AUTOSAR XML (schema 00048)
package /ComponentTypes
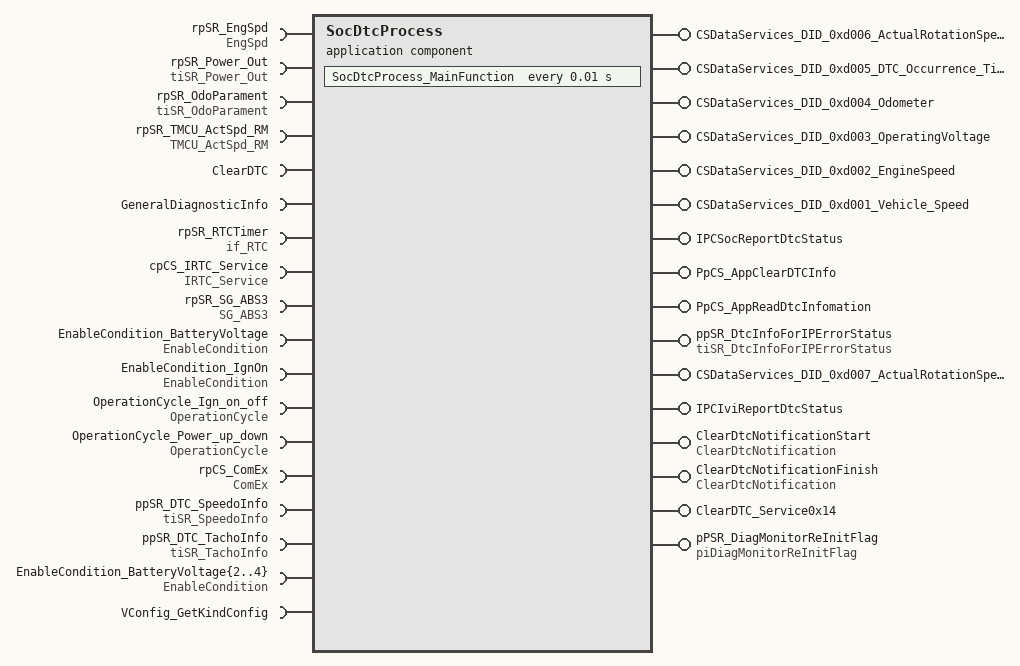
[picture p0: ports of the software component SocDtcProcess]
  application sw component type SocDtcProcess
    7 x provide port:
      CSDataServices_DID_0xd006_ActualRotationSpeed: server-com-spec{operation=ReadData, queue-length=1}, provided-interface=CSDataServices_DID_0xd006_ActualRotationSpeed
      CSDataServices_DID_0xd005_DTC_Occurrence_Timer: server-com-spec{operation=ReadData, queue-length=1}, provided-interface=CSDataServices_DID_0xd005_DTC_Occurrence_Timer
      CSDataServices_DID_0xd004_Odometer: server-com-spec{operation=ReadData, queue-length=1}, provided-interface=CSDataServices_DID_0xd004_Odometer
      CSDataServices_DID_0xd003_OperatingVoltage: server-com-spec{operation=ReadData, queue-length=1}, provided-interface=CSDataServices_DID_0xd003_OperatingVoltage
      CSDataServices_DID_0xd002_EngineSpeed: server-com-spec{operation=ReadData, queue-length=1}, provided-interface=CSDataServices_DID_0xd002_EngineSpeed
      CSDataServices_DID_0xd001_Vehicle_Speed: server-com-spec{operation=ReadData, queue-length=1}, provided-interface=CSDataServices_DID_0xd001_Vehicle_Speed
      IPCSocReportDtcStatus: server-com-spec{operation=IpcSocReportDtcStatus, queue-length=1}, provided-interface=IPCSocReportDtcStatus
    6 x require port:
      rpSR_EngSpd: nonqueued-receiver-com-spec{data-element=EngSpd, alive-timeout=100, filter=data-filter-type=ALWAYS, handle-never-received=true, init-value=0}, required-interface=EngSpd
      rpSR_Power_Out: nonqueued-receiver-com-spec{data-element=SystemStateOut, alive-timeout=100, filter=data-filter-type=ALWAYS, init-value=constant-reference=PowerOutInit}, required-interface=tiSR_Power_Out
      rpSR_OdoParament: nonqueued-receiver-com-spec{data-element=Element, alive-timeout=100, filter=data-filter-type=ALWAYS, handle-never-received=true, init-value=constant-reference=SocRpOdoDataInit}, required-interface=tiSR_OdoParament
      rpSR_TMCU_ActSpd_RM: nonqueued-receiver-com-spec{data-element=TMCU_ActSpd_RM, alive-timeout=100, filter=data-filter-type=ALWAYS, handle-never-received=true, init-value=0}, required-interface=TMCU_ActSpd_RM
      ClearDTC: required-com-specs=[SelectDTC, ClearDTC], required-interface=ClearDTC
      GeneralDiagnosticInfo: required-interface=GeneralDiagnosticInfo
        required-com-specs:
          GetMonitorStatus
          GetDebouncingOfEvent
          GetEventEnableCondition
          GetEventExtendedDataRecordEx
          GetEventFreezeFrameDataEx
          GetFaultDetectionCounter
          GetDTCOfEvent
          GetEventTested
          GetEventFailed
          GetEventStatus
          GetEventUdsStatus
    provide port PpCS_AppClearDTCInfo: server-com-spec{operation=AppClearDTCInfo, queue-length=1}, provided-interface=PpCS_AppClearDTCInfo
    provide port PpCS_AppReadDtcInfomation: server-com-spec{operation=AppReadDtcInformation, queue-length=1}, provided-interface=PpCS_AppReadDtcInfomation
    require port rpSR_RTCTimer: required-interface=if_RTC
      required-com-specs:
        data-element=SleepDateTime, filter=data-filter-type=ALWAYS, init-value=0
        data-element=UtcTime, filter=data-filter-type=ALWAYS
    require port cpCS_IRTC_Service: required-com-specs=[UTC2PerpetualCalendar, GetUTCTimeInMillis], required-interface=IRTC_Service
    provide port ppSR_DtcInfoForIPErrorStatus: nonqueued-sender-com-spec{data-element=Element, init-value=0}, provided-interface=tiSR_DtcInfoForIPErrorStatus
    5 x require port:
      rpSR_SG_ABS3: nonqueued-receiver-com-spec{data-element=SG_ABS3, alive-timeout=0.2, enable-update=true, handle-never-received=true, init-value=fields=[ABSActv_0x265:0, ABSFailSts_0x265:1, CheckSum_ABS3_0x265:0, dummy_ABS3_0:0, dummy_ABS3_1:0, dummy_ABS3_2:0, dummy_ABS3_3:0, EBDActv_0x265:0, EBDFailSts_0x265:0, RollingCounter_ABS3_0x265:0, VehOdoInfo_0x265:0, VehOdoInfoSts_0x265:1, VehSpd_0x265:0, VehSpdVld_0x265:0]}, required-interface=SG_ABS3
      EnableCondition_BatteryVoltage: client-com-spec=SetEnableCondition, required-interface=EnableCondition
      EnableCondition_IgnOn: client-com-spec=SetEnableCondition, required-interface=EnableCondition
      OperationCycle_Ign_on_off: required-com-specs=[SetOperationCycleState, GetOperationCycleState], required-interface=OperationCycle
      OperationCycle_Power_up_down: required-com-specs=[SetOperationCycleState, GetOperationCycleState], required-interface=OperationCycle
    6 x provide port:
      CSDataServices_DID_0xd007_ActualRotationSpeed02: server-com-spec{operation=ReadData, queue-length=1}, provided-interface=CSDataServices_DID_0xd007_ActualRotationSpeed02
      IPCIviReportDtcStatus: server-com-spec{operation=IpcIviReportDtcSts, queue-length=1}, provided-interface=IPCIviReportDtcStatus
      ClearDtcNotificationStart: server-com-spec{operation=ClearDtcNotification, queue-length=1}, provided-interface=ClearDtcNotification
      ClearDtcNotificationFinish: server-com-spec{operation=ClearDtcNotification, queue-length=1}, provided-interface=ClearDtcNotification
      ClearDTC_Service0x14: nonqueued-sender-com-spec{data-element=StatusFlag, init-value=0}, provided-interface=ClearDTC_Service0x14
      pPSR_DiagMonitorReInitFlag: nonqueued-sender-com-spec{data-element=ChangeCounter, init-value=0}, provided-interface=piDiagMonitorReInitFlag
    7 x require port:
      rpCS_ComEx: required-com-specs=[SendSignal, ReceiveSignal, GetRxE2EStatus], required-interface=ComEx
      ppSR_DTC_SpeedoInfo: nonqueued-receiver-com-spec{data-element=Element, filter=data-filter-type=ALWAYS, init-value=fields=[OverSpdWrnFlg:0, VehRunSts:0, IndicateSpeed:0, RealSpeed:0, IndicateSpeedMile:0, RealSpeedMile:0, RealSpeedBak:0, Msg_missingSts:0, VehSpdVld:0]}, required-interface=tiSR_SpeedoInfo
      ppSR_DTC_TachoInfo: nonqueued-receiver-com-spec{data-element=Element, filter=data-filter-type=ALWAYS, init-value=fields=[EngRunSts:0, EngSpd:0, TimeOutFlag:0, EngSpdBak:0, Msg_missingSts:0]}, required-interface=tiSR_TachoInfo
      EnableCondition_BatteryVoltage{2..4}: client-com-spec=SetEnableCondition, required-interface=EnableCondition
      VConfig_GetKindConfig: client-com-spec=Operation_VConfig_GetKindConfig, required-interface=VConfig_GetKindConfig
    behavior SocDtcProcess_InternalBehavior
      exclusive area SocDtcPorcessExclusiveArea
      init event SocDtcProcess_InitEvent: start-on-event=SocDtcProcess_Init
      timing event TMT_SocDtcProcess_MainFunction: start-on-event=SocDtcProcess_MainFunction, period=0.01
      13 x operation invoked event:
        OIT_CSDataServices_DID_0xd006_ActualRotationSpeed_ReadData_CSDataServices_DID_0xd006_ActualRotationSpeed_ReadData: start-on-event=CSDataServices_DID_0xd006_ActualRotationSpeed_ReadData, operation=CSDataServices_DID_0xd006_ActualRotationSpeed.ReadData
        OIT_CSDataServices_DID_0xd001_Vehicle_Speed_ReadData_CSDataServices_DID_0xd001_Vehicle_Speed_ReadData: start-on-event=CSDataServices_DID_0xd001_Vehicle_Speed_ReadData, operation=CSDataServices_DID_0xd001_Vehicle_Speed.ReadData
        OIT_CSDataServices_DID_0xd004_Odometer_ReadData_CSDataServices_DID_0xd004_Odometer_ReadData: start-on-event=CSDataServices_DID_0xd004_Odometer_ReadData, operation=CSDataServices_DID_0xd004_Odometer.ReadData
        OIT_CSDataServices_DID_0xd005_DTC_Occurrence_Timer_ReadData_CSDataServices_DID_0xd005_DTC_Occurrence_Timer_ReadData: start-on-event=CSDataServices_DID_0xd005_DTC_Occurrence_Timer_ReadData, operation=CSDataServices_DID_0xd005_DTC_Occurrence_Timer.ReadData
        OIT_CSDataServices_DID_0xd003_OperatingVoltage_ReadData_CSDataServices_DID_0xd003_OperatingVoltage_ReadData: start-on-event=CSDataServices_DID_0xd003_OperatingVoltage_ReadData, operation=CSDataServices_DID_0xd003_OperatingVoltage.ReadData
        OIT_CSDataServices_DID_0xd002_EngineSpeed_ReadData_CSDataServices_DID_0xd002_EngineSpeed_ReadData: start-on-event=CSDataServices_DID_0xd002_EngineSpeed_ReadData, operation=CSDataServices_DID_0xd002_EngineSpeed.ReadData
        OIT_IPCSocReportDtcStatus_IpcSocReportDtcStatus_IPCSocReportDtcStatus_IpcSocReportDtcStatus: start-on-event=IPCSocReportDtcStatus_IpcSocReportDtcStatus, operation=IPCSocReportDtcStatus.IpcSocReportDtcStatus
        OIT_PpCS_AppClearDTCInfo_AppClearDTCInfo_PpCS_AppClearDTCInfo_AppClearDTCInfo: start-on-event=PpCS_AppClearDTCInfo_AppClearDTCInfo, operation=PpCS_AppClearDTCInfo.AppClearDTCInfo
        OIT_PpCS_AppReadDtcInfomation_AppReadDtcInformation_PpCS_AppReadDtcInfomation_AppReadDtcInformation: start-on-event=PpCS_AppReadDtcInfomation_AppReadDtcInformation, operation=PpCS_AppReadDtcInfomation.AppReadDtcInformation
        OIT_CSDataServices_DID_0xd007_ActualRotationSpeed02_ReadData_CSDataServices_DID_0xd007_ActualRotationSpeed02_ReadData: start-on-event=CSDataServices_DID_0xd007_ActualRotationSpeed02_ReadData, operation=CSDataServices_DID_0xd007_ActualRotationSpeed02.ReadData
        OIT_IPCIviReportDtcStatus_IpcIviReportDtcSts_IPCIviReportDtcStatus_IpcIviReportDtcSts: start-on-event=IPCIviReportDtcStatus_IpcIviReportDtcSts, operation=IPCIviReportDtcStatus.IpcIviReportDtcSts
        OIT_ClearDtcNotificationStart_ClearDtcNotification_ClearDtcNotificationStart_ClearDtcNotification: start-on-event=ClearDtcNotificationStart_ClearDtcNotification, operation=ClearDtcNotificationStart.ClearDtcNotification
        OIT_ClearDtcNotificationFinish_ClearDtcNotification_ClearDtcNotificationFinish_ClearDtcNotification: start-on-event=ClearDtcNotificationFinish_ClearDtcNotification, operation=ClearDtcNotificationFinish.ClearDtcNotification
      port-api-options:
        enable-take-address=true, error-handling=NO-TRANSFORMER-ERROR-HANDLING, indirect-api=false, port=CSDataServices_DID_0xd001_Vehicle_Speed
        enable-take-address=true, error-handling=NO-TRANSFORMER-ERROR-HANDLING, indirect-api=false, port=CSDataServices_DID_0xd002_EngineSpeed
        enable-take-address=true, error-handling=NO-TRANSFORMER-ERROR-HANDLING, indirect-api=false, port=CSDataServices_DID_0xd003_OperatingVoltage
        enable-take-address=true, error-handling=NO-TRANSFORMER-ERROR-HANDLING, indirect-api=false, port=CSDataServices_DID_0xd004_Odometer
        enable-take-address=true, error-handling=NO-TRANSFORMER-ERROR-HANDLING, indirect-api=false, port=CSDataServices_DID_0xd005_DTC_Occurrence_Timer
        enable-take-address=true, error-handling=NO-TRANSFORMER-ERROR-HANDLING, indirect-api=false, port=CSDataServices_DID_0xd006_ActualRotationSpeed
        enable-take-address=true, error-handling=NO-TRANSFORMER-ERROR-HANDLING, indirect-api=false, port=PpCS_AppClearDTCInfo
        enable-take-address=true, error-handling=NO-TRANSFORMER-ERROR-HANDLING, indirect-api=false, port=PpCS_AppReadDtcInfomation
        enable-take-address=true, error-handling=NO-TRANSFORMER-ERROR-HANDLING, indirect-api=false, port=IPCIviReportDtcStatus
        enable-take-address=true, error-handling=NO-TRANSFORMER-ERROR-HANDLING, indirect-api=false, port=pPSR_DiagMonitorReInitFlag
      15 x runnable:
        SocDtcProcess_Init
        SocDtcProcess_MainFunction
          data-receive-point-by-arguments:
            9 x access:
              REC_rpSR_EngSpd_EngSpd: accessed-variable=rpSR_EngSpd.EngSpd
              REC_rpSR_Power_Out_SystemStateOut: accessed-variable=rpSR_Power_Out.SystemStateOut
              REC_rpSR_OdoParament_Element: accessed-variable=rpSR_OdoParament.Element
              REC_rpSR_TMCU_ActSpd_RM_TMCU_ActSpd_RM: accessed-variable=rpSR_TMCU_ActSpd_RM.TMCU_ActSpd_RM
              REC_rpSR_SG_ABS3_SG_ABS3: accessed-variable=rpSR_SG_ABS3.SG_ABS3
              REC_rpSR_RTCTimer_SleepDateTime: accessed-variable=rpSR_RTCTimer.SleepDateTime
              REC_rpSR_RTCTimer_UtcTime: accessed-variable=rpSR_RTCTimer.UtcTime
              REC_ppSR_DTC_SpeedoInfo_Element: accessed-variable=ppSR_DTC_SpeedoInfo.Element
              REC_ppSR_DTC_TachoInfo_Element: accessed-variable=ppSR_DTC_TachoInfo.Element
          data-send-points:
            access SEND_ppSR_DtcInfoForIPErrorStatus_Element: accessed-variable=ppSR_DtcInfoForIPErrorStatus.Element
            access SEND_pPSR_kl15OperationCycleChangeFlag_Element: accessed-variable=pPSR_DiagMonitorReInitFlag.ChangeCounter
          14 x sync call:
            SC_EnableCondition_SetEnableCondition: operation=EnableCondition_BatteryVoltage.SetEnableCondition
            SC_EnableCondition_IgnOn_SetEnableCondition: operation=EnableCondition_IgnOn.SetEnableCondition
            SC_OperationCycle_Ign_on_off_GetOperationCycleState: operation=OperationCycle_Ign_on_off.GetOperationCycleState
            SC_OperationCycle_Ign_on_off_SetOperationCycleState: operation=OperationCycle_Ign_on_off.SetOperationCycleState
            SC_OperationCycle_Power_up_down_GetOperationCycleState: operation=OperationCycle_Power_up_down.GetOperationCycleState
            SC_OperationCycle_Power_up_down_SetOperationCycleState: operation=OperationCycle_Power_up_down.SetOperationCycleState
            SC_rpCS_ComEx_GetRxE2EStatus: operation=rpCS_ComEx.GetRxE2EStatus
            SC_rpCS_ComEx_ReceiveSignal: operation=rpCS_ComEx.ReceiveSignal
            SC_rpCS_ComEx_SendSignal: operation=rpCS_ComEx.SendSignal
            SC_cpCS_IRTC_Service_UTC2PerpetualCalendar: operation=cpCS_IRTC_Service.UTC2PerpetualCalendar
            SC_EnableCondition_BatteryVoltage{2..4}_SetEnableCondition: operation=EnableCondition_BatteryVoltage{2..4}.SetEnableCondition
            SC_VConfig_GetKindConfig_Operation_VConfig_GetKindConfig: operation=VConfig_GetKindConfig.Operation_VConfig_GetKindConfig
        CSDataServices_DID_0xd006_ActualRotationSpeed_ReadData: can-be-invoked-concurrently=true
        CSDataServices_DID_0xd001_Vehicle_Speed_ReadData: can-be-invoked-concurrently=true
        CSDataServices_DID_0xd004_Odometer_ReadData: can-be-invoked-concurrently=true
        CSDataServices_DID_0xd005_DTC_Occurrence_Timer_ReadData: can-be-invoked-concurrently=true
          data-receive-point-by-arguments:
            access REC_rpSR_RTCTimer_UtcTime: accessed-variable=rpSR_RTCTimer.UtcTime
          sync call SC_cpCS_IRTC_Service_UTC2PerpetualCalendar: operation=cpCS_IRTC_Service.UTC2PerpetualCalendar
        CSDataServices_DID_0xd003_OperatingVoltage_ReadData: can-be-invoked-concurrently=true
        CSDataServices_DID_0xd002_EngineSpeed_ReadData: can-be-invoked-concurrently=true
        IPCSocReportDtcStatus_IpcSocReportDtcStatus
        PpCS_AppClearDTCInfo_AppClearDTCInfo
          sync call SC_ClearDTC_ClearDTC: operation=ClearDTC.ClearDTC
          sync call SC_ClearDTC_SelectDTC: operation=ClearDTC.SelectDTC
        PpCS_AppReadDtcInfomation_AppReadDtcInformation: can-enter-exclusive-area=SocDtcPorcessExclusiveArea
          11 x sync call:
            SC_GeneralDiagnosticInfo_GetDTCOfEvent: operation=GeneralDiagnosticInfo.GetDTCOfEvent
            SC_GeneralDiagnosticInfo_GetDebouncingOfEvent: operation=GeneralDiagnosticInfo.GetDebouncingOfEvent
            SC_GeneralDiagnosticInfo_GetEventEnableCondition: operation=GeneralDiagnosticInfo.GetEventEnableCondition
            SC_GeneralDiagnosticInfo_GetEventExtendedDataRecordEx: operation=GeneralDiagnosticInfo.GetEventExtendedDataRecordEx
            SC_GeneralDiagnosticInfo_GetEventFailed: operation=GeneralDiagnosticInfo.GetEventFailed
            SC_GeneralDiagnosticInfo_GetEventFreezeFrameDataEx: operation=GeneralDiagnosticInfo.GetEventFreezeFrameDataEx
            SC_GeneralDiagnosticInfo_GetEventStatus: operation=GeneralDiagnosticInfo.GetEventStatus
            SC_GeneralDiagnosticInfo_GetEventTested: operation=GeneralDiagnosticInfo.GetEventTested
            SC_GeneralDiagnosticInfo_GetEventUdsStatus: operation=GeneralDiagnosticInfo.GetEventUdsStatus
            SC_GeneralDiagnosticInfo_GetFaultDetectionCounter: operation=GeneralDiagnosticInfo.GetFaultDetectionCounter
            SC_GeneralDiagnosticInfo_GetMonitorStatus: operation=GeneralDiagnosticInfo.GetMonitorStatus
        CSDataServices_DID_0xd007_ActualRotationSpeed02_ReadData
        IPCIviReportDtcStatus_IpcIviReportDtcSts
        ClearDtcNotificationStart_ClearDtcNotification
          data-send-points:
            access SEND_pPSR_DiagMonitorReInitFlag_ChangeCounter: accessed-variable=pPSR_DiagMonitorReInitFlag.ChangeCounter
        ClearDtcNotificationFinish_ClearDtcNotification
          data-send-points:
            access SEND_ClearDTC_Service0x14_StatusFlag: accessed-variable=ClearDTC_Service0x14.StatusFlag
  swc implementation SocDtcProcess_Implementation: behavior=SocDtcProcess_InternalBehavior
